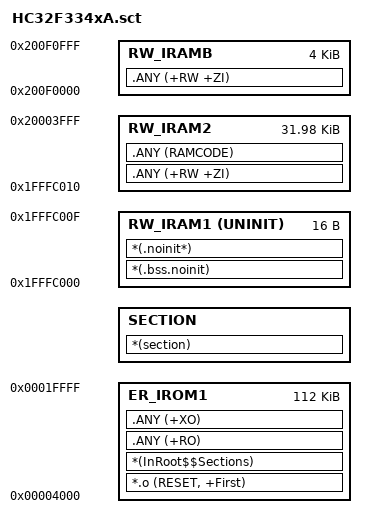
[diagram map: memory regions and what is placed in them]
; ****************************************************************
; Scatter-Loading Description File
; ****************************************************************
LR_IROM1 0x00004000 0x0001C000  {    ; load region size_region
    ER_IROM1 0x00004000 0x0001C000  {  ; load address = execution address
        *.o (RESET, +First)
        *(InRoot$$Sections)
        .ANY (+RO)
        .ANY (+XO)
    }
    SECTION AlignExpr(+0, 4)  {  ; auto-registration table
        *(section)
    }
    RW_IRAM1 0x1FFFC000  UNINIT 0x00000010   {  ; retained boot handoff data
        *(.bss.noinit)
        *(.noinit*)
    }
    RW_IRAM2 0x1FFFC010  0x00007FF0   {  ; RW data
        .ANY (+RW +ZI)
        .ANY (RAMCODE)
    }
    RW_IRAMB 0x200F0000 0x00001000  {  ; RW data
        .ANY (+RW +ZI)
    }
}
